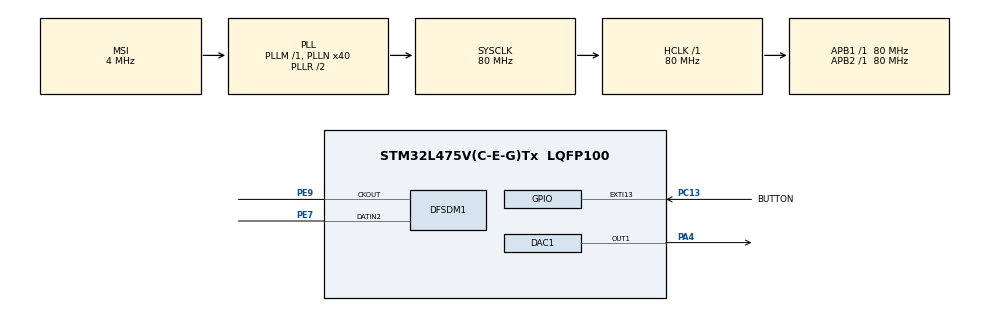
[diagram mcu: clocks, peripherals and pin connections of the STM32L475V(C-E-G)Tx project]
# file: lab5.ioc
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Mcu.Family=STM32L4
RCC.MSI_VALUE=4000000
Dma.DAC_CH1.0.Mode=DMA_CIRCULAR
Dma.DFSDM1_FLT0.1.Priority=DMA_PRIORITY_LOW
Dma.DAC_CH1.0.MemDataAlignment=DMA_MDATAALIGN_WORD
RCC.CortexFreq_Value=80000000
PC13.Signal=GPXTI13
Dma.DFSDM1_FLT0.1.Direction=DMA_PERIPH_TO_MEMORY
SH.S_DATAIN2DFSDM1.0=DFSDM1_DATIN2,PDM_SPI_input_from_ch2_and_internal_clock
PC13.GPIO_Label=BUTTON
Dma.DFSDM1_FLT0.1.PeriphInc=DMA_PINC_DISABLE
RCC.SYSCLKSource=RCC_SYSCLKSOURCE_PLLCLK
ProjectManager.StackSize=0x400
PB3\ (JTDO-TRACESWO).Signal=SYS_JTDO-SWO
NVIC.DMA1_Channel3_IRQn=true\:0\:0\:false\:false\:true\:false\:true
Dma.DAC_CH1.0.Direction=DMA_MEMORY_TO_PERIPH
Dma.DAC_CH1.0.Instance=DMA1_Channel3
ProjectManager.TargetToolchain=STM32CubeIDE
SH.COMP_DAC11_group.0=DAC1_OUT1,DAC_OUT1
RCC.HCLKFreq_Value=80000000
RCC.APB2TimFreq_Value=80000000
Dma.DFSDM1_FLT0.1.Mode=DMA_NORMAL
Dma.DAC_CH1.0.MemInc=DMA_MINC_ENABLE
Dma.DFSDM1_FLT0.1.MemInc=DMA_MINC_ENABLE
RCC.USBFreq_Value=48000000
RCC.LSE_VALUE=32768
RCC.AHBFreq_Value=80000000
NVIC.EXTI15_10_IRQn=true\:0\:0\:false\:false\:true\:true\:true
RCC.HSE_VALUE=8000000
board=B-L475E-IOT01A1
Dma.DFSDM1_FLT0.1.MemDataAlignment=DMA_MDATAALIGN_WORD
RCC.VCOOutputFreq_Value=160000000
DFSDM1.FastMode_reg_FIL0=ENABLE
RCC.APB2Freq_Value=80000000
VP_TIM2_VS_ClockSourceINT.Mode=Internal
PE9.Signal=S_CKOUTDFSDM1
SH.S_CKOUTDFSDM1.0=DFSDM1_CKOUT,PDM_SPI_input_from_ch2_and_internal_clock
SH.S_CKOUTDFSDM1.1=DFSDM1_CKOUT,CKOUT
NVIC.TIM2_IRQn=true\:0\:0\:false\:false\:true\:true\:true
RCC.ADCFreq_Value=48000000
Dma.DAC_CH1.0.PeriphDataAlignment=DMA_PDATAALIGN_WORD
Dma.DFSDM1_FLT0.1.Instance=DMA1_Channel4
DFSDM1.Fosr_FIL0=100
DAC1.DAC_Trigger-DAC_OUT1=DAC_TRIGGER_T2_TRGO
TIM2.Period=4000
Mcu.Name=STM32L475V(C-E-G)Tx
Dma.DAC_CH1.0.PeriphInc=DMA_PINC_DISABLE
PA4.Signal=COMP_DAC11_group
RCC.SYSCLKFreq_VALUE=80000000
Mcu.Package=LQFP100
Dma.DFSDM1_FLT0.1.PeriphDataAlignment=DMA_PDATAALIGN_WORD
PC13.GPIO_ModeDefaultEXTI=GPIO_MODE_IT_FALLING
ProjectManager.HeapSize=0x200
Dma.DAC_CH1.0.Priority=DMA_PRIORITY_LOW
RCC.HSI_VALUE=16000000
NVIC.PriorityGroup=NVIC_PRIORITYGROUP_4
TIM2.TIM_MasterOutputTrigger=TIM_TRGO_UPDATE
DFSDM1.DmaMode_reg_FIL0=ENABLE
RCC.PLLN=40
Dma.Request1=DFSDM1_FLT0
RCC.APB1TimFreq_Value=80000000
DFSDM1.Filter_regChannel_FIL1=__NULL
DFSDM1.Divider=40
NVIC.DMA1_Channel4_IRQn=true\:0\:0\:false\:false\:true\:false\:true
PE7.Signal=S_DATAIN2DFSDM1
PA13\ (JTMS-SWDIO).Signal=SYS_JTMS-SWDIO
DFSDM1.Filter_regChannel_FIL0=DFSDM_CHANNEL_2
Dma.Request0=DAC_CH1
RCC.APB1Freq_Value=80000000
DFSDM1.SincOrder_FIL0=DFSDM_FILTER_SINC3_ORDER
RCC.PLLSAI1N=24

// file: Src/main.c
/* USER CODE BEGIN Header */
/**
  ******************************************************************************
  * @file           : main.c
  * @brief          : Main program body
  ******************************************************************************
  * @attention
  *
  * <h2><center>&copy; Copyright (c) 2020 STMicroelectronics.
  * All rights reserved.</center></h2>
  *
  * This software component is licensed by ST under BSD 3-Clause license,
  * the "License"; You may not use this file except in compliance with the
  * License. You may obtain a copy of the License at:
  *                        opensource.org/licenses/BSD-3-Clause
  *
  ******************************************************************************
  */
/* USER CODE END Header */
#include "main.h"

DAC_HandleTypeDef hdac1;
DMA_HandleTypeDef hdma_dac_ch1;

DFSDM_Filter_HandleTypeDef hdfsdm1_filter0;
DFSDM_Channel_HandleTypeDef hdfsdm1_channel2;
DMA_HandleTypeDef hdma_dfsdm1_flt0;

TIM_HandleTypeDef htim2;

/* USER CODE BEGIN PV */
#define BufferSize  22000
int32_t audioBuffer[BufferSize];

/* USER CODE END PV */

void SystemClock_Config(void);
static void MX_GPIO_Init(void);
static void MX_DMA_Init(void);
static void MX_DAC1_Init(void);
static void MX_TIM2_Init(void);
static void MX_DFSDM1_Init(void);

int main(void)
{

  /* MCU Configuration--------------------------------------------------------*/

  /* Reset of all peripherals, Initializes the Flash interface and the Systick. */
  HAL_Init();

  /* Configure the system clock */
  SystemClock_Config();

  /* Initialize all configured peripherals */
  MX_GPIO_Init();
  MX_DMA_Init();
  MX_DAC1_Init();
  MX_TIM2_Init();
  MX_DFSDM1_Init();
  /* USER CODE BEGIN 2 */
  HAL_TIM_Base_Start(&htim2);
  for(int i = 0 ; i<18000 ; i++){
	  audioBuffer[i] = 0;
  }
  /* USER CODE END 2 */

  /* Infinite loop */
  while (1)
  {

  }
}

void SystemClock_Config(void)
{
  RCC_OscInitTypeDef RCC_OscInitStruct = {0};
  RCC_ClkInitTypeDef RCC_ClkInitStruct = {0};
  RCC_PeriphCLKInitTypeDef PeriphClkInit = {0};

  /** Initializes the RCC Oscillators according to the specified parameters
  * in the RCC_OscInitTypeDef structure.
  */
  RCC_OscInitStruct.OscillatorType = RCC_OSCILLATORTYPE_MSI;
  RCC_OscInitStruct.MSIState = RCC_MSI_ON;
  RCC_OscInitStruct.MSICalibrationValue = 0;
  RCC_OscInitStruct.MSIClockRange = RCC_MSIRANGE_6;
  RCC_OscInitStruct.PLL.PLLState = RCC_PLL_ON;
  RCC_OscInitStruct.PLL.PLLSource = RCC_PLLSOURCE_MSI;
  RCC_OscInitStruct.PLL.PLLM = 1;
  RCC_OscInitStruct.PLL.PLLN = 40;
  RCC_OscInitStruct.PLL.PLLP = RCC_PLLP_DIV7;
  RCC_OscInitStruct.PLL.PLLQ = RCC_PLLQ_DIV2;
  RCC_OscInitStruct.PLL.PLLR = RCC_PLLR_DIV2;
  if (HAL_RCC_OscConfig(&RCC_OscInitStruct) != HAL_OK)
  {
    Error_Handler();
  }
  /** Initializes the CPU, AHB and APB buses clocks
  */
  RCC_ClkInitStruct.ClockType = RCC_CLOCKTYPE_HCLK|RCC_CLOCKTYPE_SYSCLK
                              |RCC_CLOCKTYPE_PCLK1|RCC_CLOCKTYPE_PCLK2;
  RCC_ClkInitStruct.SYSCLKSource = RCC_SYSCLKSOURCE_PLLCLK;
  RCC_ClkInitStruct.AHBCLKDivider = RCC_SYSCLK_DIV1;
  RCC_ClkInitStruct.APB1CLKDivider = RCC_HCLK_DIV1;
  RCC_ClkInitStruct.APB2CLKDivider = RCC_HCLK_DIV1;

  if (HAL_RCC_ClockConfig(&RCC_ClkInitStruct, FLASH_LATENCY_4) != HAL_OK)
  {
    Error_Handler();
  }
  PeriphClkInit.PeriphClockSelection = RCC_PERIPHCLK_DFSDM1;
  PeriphClkInit.Dfsdm1ClockSelection = RCC_DFSDM1CLKSOURCE_PCLK;
  if (HAL_RCCEx_PeriphCLKConfig(&PeriphClkInit) != HAL_OK)
  {
    Error_Handler();
  }
  /** Configure the main internal regulator output voltage
  */
  if (HAL_PWREx_ControlVoltageScaling(PWR_REGULATOR_VOLTAGE_SCALE1) != HAL_OK)
  {
    Error_Handler();
  }
}

static void MX_DAC1_Init(void)
{

  DAC_ChannelConfTypeDef sConfig = {0};

  /** DAC Initialization
  */
  hdac1.Instance = DAC1;
  if (HAL_DAC_Init(&hdac1) != HAL_OK)
  {
    Error_Handler();
  }
  /** DAC channel OUT1 config
  */
  sConfig.DAC_SampleAndHold = DAC_SAMPLEANDHOLD_DISABLE;
  sConfig.DAC_Trigger = DAC_TRIGGER_T2_TRGO;
  sConfig.DAC_OutputBuffer = DAC_OUTPUTBUFFER_ENABLE;
  sConfig.DAC_ConnectOnChipPeripheral = DAC_CHIPCONNECT_DISABLE;
  sConfig.DAC_UserTrimming = DAC_TRIMMING_FACTORY;
  if (HAL_DAC_ConfigChannel(&hdac1, &sConfig, DAC_CHANNEL_1) != HAL_OK)
  {
    Error_Handler();
  }

}

static void MX_DFSDM1_Init(void)
{

  hdfsdm1_filter0.Instance = DFSDM1_Filter0;
  hdfsdm1_filter0.Init.RegularParam.Trigger = DFSDM_FILTER_SW_TRIGGER;
  hdfsdm1_filter0.Init.RegularParam.FastMode = ENABLE;
  hdfsdm1_filter0.Init.RegularParam.DmaMode = ENABLE;
  hdfsdm1_filter0.Init.FilterParam.SincOrder = DFSDM_FILTER_SINC3_ORDER;
  hdfsdm1_filter0.Init.FilterParam.Oversampling = 100;
  hdfsdm1_filter0.Init.FilterParam.IntOversampling = 1;
  if (HAL_DFSDM_FilterInit(&hdfsdm1_filter0) != HAL_OK)
  {
    Error_Handler();
  }
  hdfsdm1_channel2.Instance = DFSDM1_Channel2;
  hdfsdm1_channel2.Init.OutputClock.Activation = ENABLE;
  hdfsdm1_channel2.Init.OutputClock.Selection = DFSDM_CHANNEL_OUTPUT_CLOCK_SYSTEM;
  hdfsdm1_channel2.Init.OutputClock.Divider = 40;
  hdfsdm1_channel2.Init.Input.Multiplexer = DFSDM_CHANNEL_EXTERNAL_INPUTS;
  hdfsdm1_channel2.Init.Input.DataPacking = DFSDM_CHANNEL_STANDARD_MODE;
  hdfsdm1_channel2.Init.Input.Pins = DFSDM_CHANNEL_SAME_CHANNEL_PINS;
  hdfsdm1_channel2.Init.SerialInterface.Type = DFSDM_CHANNEL_SPI_RISING;
  hdfsdm1_channel2.Init.SerialInterface.SpiClock = DFSDM_CHANNEL_SPI_CLOCK_INTERNAL;
  hdfsdm1_channel2.Init.Awd.FilterOrder = DFSDM_CHANNEL_FASTSINC_ORDER;
  hdfsdm1_channel2.Init.Awd.Oversampling = 1;
  hdfsdm1_channel2.Init.Offset = 0;
  hdfsdm1_channel2.Init.RightBitShift = 0x00;
  if (HAL_DFSDM_ChannelInit(&hdfsdm1_channel2) != HAL_OK)
  {
    Error_Handler();
  }
  if (HAL_DFSDM_FilterConfigRegChannel(&hdfsdm1_filter0, DFSDM_CHANNEL_2, DFSDM_CONTINUOUS_CONV_ON) != HAL_OK)
  {
    Error_Handler();
  }

}

static void MX_TIM2_Init(void)
{

  TIM_ClockConfigTypeDef sClockSourceConfig = {0};
  TIM_MasterConfigTypeDef sMasterConfig = {0};

  htim2.Instance = TIM2;
  htim2.Init.Prescaler = 0;
  htim2.Init.CounterMode = TIM_COUNTERMODE_UP;
  htim2.Init.Period = 4000;
  htim2.Init.ClockDivision = TIM_CLOCKDIVISION_DIV1;
  htim2.Init.AutoReloadPreload = TIM_AUTORELOAD_PRELOAD_DISABLE;
  if (HAL_TIM_Base_Init(&htim2) != HAL_OK)
  {
    Error_Handler();
  }
  sClockSourceConfig.ClockSource = TIM_CLOCKSOURCE_INTERNAL;
  if (HAL_TIM_ConfigClockSource(&htim2, &sClockSourceConfig) != HAL_OK)
  {
    Error_Handler();
  }
  sMasterConfig.MasterOutputTrigger = TIM_TRGO_UPDATE;
  sMasterConfig.MasterSlaveMode = TIM_MASTERSLAVEMODE_DISABLE;
  if (HAL_TIMEx_MasterConfigSynchronization(&htim2, &sMasterConfig) != HAL_OK)
  {
    Error_Handler();
  }

}

static void MX_DMA_Init(void)
{

  /* DMA controller clock enable */
  __HAL_RCC_DMA1_CLK_ENABLE();

  /* DMA interrupt init */
  /* DMA1_Channel3_IRQn interrupt configuration */
  HAL_NVIC_SetPriority(DMA1_Channel3_IRQn, 0, 0);
  HAL_NVIC_EnableIRQ(DMA1_Channel3_IRQn);
  /* DMA1_Channel4_IRQn interrupt configuration */
  HAL_NVIC_SetPriority(DMA1_Channel4_IRQn, 0, 0);
  HAL_NVIC_EnableIRQ(DMA1_Channel4_IRQn);

}

static void MX_GPIO_Init(void)
{
  GPIO_InitTypeDef GPIO_InitStruct = {0};

  /* GPIO Ports Clock Enable */
  __HAL_RCC_GPIOC_CLK_ENABLE();
  __HAL_RCC_GPIOA_CLK_ENABLE();
  __HAL_RCC_GPIOE_CLK_ENABLE();
  __HAL_RCC_GPIOB_CLK_ENABLE();

  /*Configure GPIO pin : BUTTON_Pin */
  GPIO_InitStruct.Pin = BUTTON_Pin;
  GPIO_InitStruct.Mode = GPIO_MODE_IT_FALLING;
  GPIO_InitStruct.Pull = GPIO_NOPULL;
  HAL_GPIO_Init(BUTTON_GPIO_Port, &GPIO_InitStruct);

  /* EXTI interrupt init*/
  HAL_NVIC_SetPriority(EXTI15_10_IRQn, 0, 0);
  HAL_NVIC_EnableIRQ(EXTI15_10_IRQn);

}

/* USER CODE BEGIN 4 */
void HAL_GPIO_EXTI_Callback(uint16_t GPIO_Pin){
	if (HAL_GPIO_ReadPin(GPIOC, GPIO_PIN_13) != GPIO_PIN_SET) {
		HAL_DAC_Stop_DMA(&hdac1, DAC_CHANNEL_1);
		//Starting DFSDM DMA mode
		HAL_DFSDM_FilterRegularStart_DMA(&hdfsdm1_filter0, audioBuffer, BufferSize);
	}
}

void HAL_DFSDM_FilterRegConvCpltCallback(DFSDM_Filter_HandleTypeDef *hdfsdm_filter0){
	HAL_DFSDM_FilterRegularStop_DMA(&hdfsdm1_filter0);
	HAL_DAC_Start_DMA (&hdac1, DAC_CHANNEL_1, (uint32_t *) audioBuffer, BufferSize, DAC_ALIGN_12B_R);
}
/* USER CODE END 4 */

void Error_Handler(void)
{
}

/************************ (C) COPYRIGHT STMicroelectronics *****END OF FILE****/
